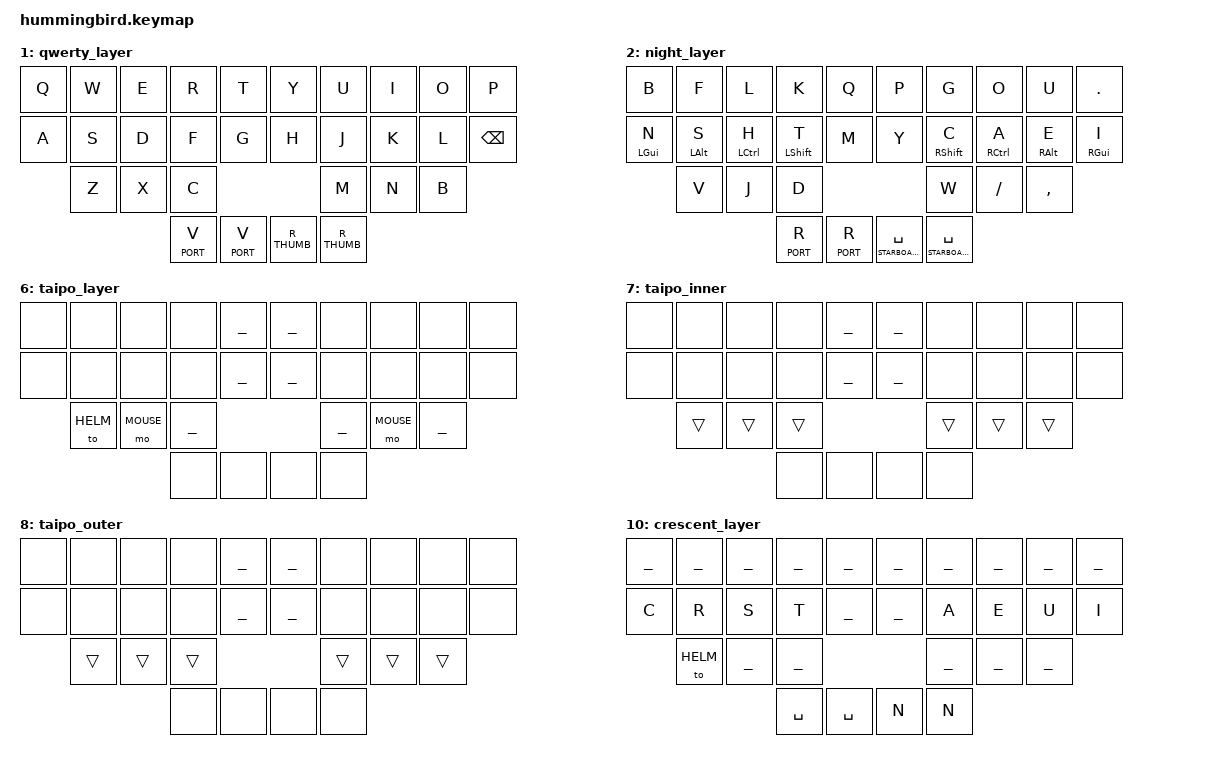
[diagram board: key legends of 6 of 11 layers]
#include "./key-labels/30.h"

#include "base.keymap"

ZMK_LAYER(helm_layer,
    // ╭─────────────┬─────────────┬─────────────┬─────────────┬─────────────╮   ╭─────────────┬─────────────┬─────────────┬─────────────┬─────────────╮
         LEFT_HELM_UPPER_ROW________________________________________________       RIGHT_HELM_UPPER_ROW_______________________________________________
    // ├─────────────┼─────────────┼─────────────┼─────────────┼─────────────┤   ├─────────────┼─────────────┼─────────────┼─────────────┼─────────────┤
         LEFT_HELM_MIDDLE_ROW_______________________________________________       RIGHT_HELM_MIDDLE_ROW______________________________________________
    // ╰─────────────┼─────────────┼─────────────┼─────────────┼─────────────╯   ╰─────────────┼─────────────┼─────────────┼─────────────┼─────────────╯
                       LEFT_HELM_LOWER_ROW____________________                                   RIGHT_HELM_LOWER_ROW___________________
    //               ╰─────────────┴─────────────┼─────────────┼─────────────╮   ╭─────────────┼─────────────┼─────────────┴─────────────╯
                                                   L_THUMB       L_THUMB           R_THUMB       R_THUMB
    //                                           ╰─────────────┴─────────────╯   ╰─────────────┴─────────────╯
)

// TODO make this qwerty
ZMK_LAYER(qwerty_layer,
    // ╭─────────────┬─────────────┬─────────────┬─────────────┬─────────────╮   ╭─────────────┬─────────────┬─────────────┬─────────────┬─────────────╮
         &kp Q         &kp W         &kp E         &kp R         &kp T             &kp Y         &kp U         &kp I         &kp O         &kp P
    // ├─────────────┼─────────────┼─────────────┼─────────────┼─────────────┤   ├─────────────┼─────────────┼─────────────┼─────────────┼─────────────┤
         &kp A         &kp S         &kp D         &kp F         &kp G             &kp H         &kp J         &kp K         &kp L         &kp BSPC
    // ╰─────────────┼─────────────┼─────────────┼─────────────┼─────────────╯   ╰─────────────┼─────────────┼─────────────┼─────────────┼─────────────╯
                       &kp Z         &kp X         &kp C                                         &kp M         &kp N         &kp B
    //               ╰─────────────┴─────────────┼─────────────┼─────────────╮   ╭─────────────┼─────────────┼─────────────┴─────────────╯
                                                   &ltp PORT V    &ltp PORT V        R_THUMB       R_THUMB
    //                                           ╰─────────────┴─────────────╯   ╰─────────────┴─────────────╯
)

// Night thumbs
#define PORT_R      &ltp PORT R
#define STARB_SPC   &lt STARBOARD SPC
// Night combos
ZMK_COMBO(night_z,     &kp Z,      LB2 LB1, NIGHT, COMBO_TERM_SLOW)
ZMK_COMBO(night_x,     &kp X,      LB3 LB2, NIGHT, COMBO_TERM_SLOW)
ZMK_COMBO(night_sqt,   &kp SQT,    RB1 RB2, NIGHT, COMBO_TERM_SLOW)
ZMK_COMBO(night_semi,  &kp SEMI,   RB2 RB3, NIGHT, COMBO_TERM_SLOW)
ZMK_LAYER(night_layer,
    // ╭─────────────┬─────────────┬─────────────┬─────────────┬─────────────╮   ╭─────────────┬─────────────┬─────────────┬─────────────┬─────────────╮
        &kp B         &kp F         &kp L         &kp K         &kp Q             &kp P         &kp G         &kp O         &kp U         &kp DOT
    // ├─────────────┼─────────────┼─────────────┼─────────────┼─────────────┤   ├─────────────┼─────────────┼─────────────┼─────────────┼─────────────┤
        &hml LGUI N   &hml LALT S   &hml LCTRL H  &hmls LSHFT T  &kp M             &kp Y         &hmrs RSHFT C  &hmr RCTRL A  &hmr RALT E   &hmr RGUI I
    // ╰─────────────┼─────────────┼─────────────┼─────────────┼─────────────╯   ╰─────────────┼─────────────┼─────────────┼─────────────┼─────────────╯
                      &kp V         &kp J         &kp D                                         &kp W         &kp SLASH     &kp COMMA
    //               ╰─────────────┴─────────────┼─────────────┼─────────────╮   ╭─────────────┼─────────────┼─────────────┴─────────────╯
                                                   PORT_R       PORT_R            STARB_SPC     STARB_SPC
    //                                           ╰─────────────┴─────────────╯   ╰─────────────┴─────────────╯
)

ZMK_LAYER(port_layer,
    // ╭─────────────┬─────────────┬─────────────┬─────────────┬─────────────╮   ╭─────────────┬─────────────┬─────────────┬─────────────┬─────────────╮
         LEFT_PORT_UPPER_ROW________________________________________________       RIGHT_PORT_UPPER_ROW_______________________________________________
    // ├─────────────┼─────────────┼─────────────┼─────────────┼─────────────┤   ├─────────────┼─────────────┼─────────────┼─────────────┼─────────────┤
         LEFT_PORT_MIDDLE_ROW_______________________________________________       RIGHT_PORT_MIDDLE_ROW______________________________________________
    // ╰─────────────┼─────────────┼─────────────┼─────────────┼─────────────╯   ╰─────────────┼─────────────┼─────────────┼─────────────┼─────────────╯
                       LEFT_PORT_LOWER_ROW____________________                                   RIGHT_PORT_LOWER_ROW___________________
    //               ╰─────────────┴─────────────┼─────────────┼─────────────╮   ╭─────────────┼─────────────┼─────────────┴─────────────╯
                                                   L_THUMB       L_THUMB           R_THUMB       R_THUMB
    //                                           ╰─────────────┴─────────────╯   ╰─────────────┴─────────────╯
)

ZMK_LAYER(starboard_layer,
    // ╭─────────────┬─────────────┬─────────────┬─────────────┬─────────────╮   ╭─────────────┬─────────────┬─────────────┬─────────────┬─────────────╮
         LEFT_STARBOARD_UPPER_ROW___________________________________________       RIGHT_STARBOARD_UPPER_ROW__________________________________________
    // ├─────────────┼─────────────┼─────────────┼─────────────┼─────────────┤   ├─────────────┼─────────────┼─────────────┼─────────────┼─────────────┤
         LEFT_STARBOARD_MIDDLE_ROW__________________________________________       RIGHT_STARBOARD_MIDDLE_ROW_________________________________________
    // ╰─────────────┼─────────────┼─────────────┼─────────────┼─────────────╯   ╰─────────────┼─────────────┼─────────────┼─────────────┼─────────────╯
                       LEFT_STARBOARD_LOWER_ROW_______________                                   RIGHT_STARBOARD_LOWER_ROW______________
    //               ╰─────────────┴─────────────┼─────────────┼─────────────╮   ╭─────────────┼─────────────┼─────────────┴─────────────╯
                                                   L_THUMB       L_THUMB           R_THUMB       R_THUMB
    //                                           ╰─────────────┴─────────────╯   ╰─────────────┴─────────────╯
)

ZMK_LAYER(aft_layer,
    // ╭─────────────┬─────────────┬─────────────┬─────────────┬─────────────╮   ╭─────────────┬─────────────┬─────────────┬─────────────┬─────────────╮
         LEFT_AFT_UPPER_ROW_________________________________________________       RIGHT_AFT_UPPER_ROW________________________________________________
    // ├─────────────┼─────────────┼─────────────┼─────────────┼─────────────┤   ├─────────────┼─────────────┼─────────────┼─────────────┼─────────────┤
         LEFT_AFT_MIDDLE_ROW________________________________________________       RIGHT_AFT_MIDDLE_ROW_______________________________________________
    // ╰─────────────┼─────────────┼─────────────┼─────────────┼─────────────╯   ╰─────────────┼─────────────┼─────────────┼─────────────┼─────────────╯
                       LEFT_AFT_LOWER_ROW_____________________                                   RIGHT_AFT_LOWER_ROW____________________
    //               ╰─────────────┴─────────────┼─────────────┼─────────────╮   ╭─────────────┼─────────────┼─────────────┴─────────────╯
                                                   L_THUMB       L_THUMB           R_THUMB       R_THUMB
    //                                           ╰─────────────┴─────────────╯   ╰─────────────┴─────────────╯
)

ZMK_LAYER(taipo_layer,
    // ╭─────────────┬─────────────┬─────────────┬─────────────┬─────────────╮   ╭─────────────┬─────────────┬─────────────┬─────────────┬─────────────╮
         &none         &none         &none         &none         ___               ___           &none         &none         &none         &none
    // ├─────────────┼─────────────┼─────────────┼─────────────┼─────────────┤   ├─────────────┼─────────────┼─────────────┼─────────────┼─────────────┤
         &none         &none         &none         &none         ___               ___           &none         &none         &none         &none
    // ╰─────────────┼─────────────┼─────────────┼─────────────┼─────────────╯   ╰─────────────┼─────────────┼─────────────┼─────────────┼─────────────╯
                       &to HELM      &mo MOUSE     ___                                           ___           &mo MOUSE     ___
    //               ╰─────────────┴─────────────┼─────────────┼─────────────╮   ╭─────────────┼─────────────┼─────────────┴─────────────╯
                                                   &none         &none             &none         &none
    //                                           ╰─────────────┴─────────────╯   ╰─────────────┴─────────────╯
)
// Add momentary mouse to both thumbs
ZMK_COMBO(Lmouse, &mo MOUSE, ITL OTL, TAIPO, COMBO_TERM_FAST)
ZMK_COMBO(Rmouse, &mo MOUSE, ITR OTR, TAIPO, COMBO_TERM_FAST)
ZMK_COMBO(Bmouse, &mo MOUSE, ITL ITR, TAIPO, COMBO_TERM_FAST)

ZMK_LAYER(taipo_inner,
    // ╭─────────────┬─────────────┬─────────────┬─────────────┬─────────────╮   ╭─────────────┬─────────────┬─────────────┬─────────────┬─────────────╮
         &none         &none         &none         &none         ___               ___           &none         &none         &none         &none
    // ├─────────────┼─────────────┼─────────────┼─────────────┼─────────────┤   ├─────────────┼─────────────┼─────────────┼─────────────┼─────────────┤
         &none         &none         &none         &none         ___               ___           &none         &none         &none         &none
    // ╰─────────────┼─────────────┼─────────────┼─────────────┼─────────────╯   ╰─────────────┼─────────────┼─────────────┼─────────────┼─────────────╯
                       &trans        &trans        &trans                                        &trans        &trans        &trans
    //               ╰─────────────┴─────────────┼─────────────┼─────────────╮   ╭─────────────┼─────────────┼─────────────┴─────────────╯
                                                   &none         &none             &none         &none
    //                                           ╰─────────────┴─────────────╯   ╰─────────────┴─────────────╯
)

ZMK_LAYER(taipo_outer,
    // ╭─────────────┬─────────────┬─────────────┬─────────────┬─────────────╮   ╭─────────────┬─────────────┬─────────────┬─────────────┬─────────────╮
         &none         &none         &none         &none         ___               ___           &none         &none         &none         &none
    // ├─────────────┼─────────────┼─────────────┼─────────────┼─────────────┤   ├─────────────┼─────────────┼─────────────┼─────────────┼─────────────┤
         &none         &none         &none         &none         ___               ___           &none         &none         &none         &none
    // ╰─────────────┼─────────────┼─────────────┼─────────────┼─────────────╯   ╰─────────────┼─────────────┼─────────────┼─────────────┼─────────────╯
                       &trans        &trans        &trans                                        &trans        &trans        &trans
    //               ╰─────────────┴─────────────┼─────────────┼─────────────╮   ╭─────────────┼─────────────┼─────────────┴─────────────╯
                                                   &none         &none             &none         &none
    //                                           ╰─────────────┴─────────────╯   ╰─────────────┴─────────────╯
)

ZMK_LAYER(mouse_layer,
    // ╭─────────────┬─────────────┬─────────────┬─────────────┬─────────────╮   ╭─────────────┬─────────────┬─────────────┬─────────────┬─────────────╮
         MOUSE_SCROLL_________________________________________   ___               ___           MOUSE_SCROLL_________________________________________
    // ├─────────────┼─────────────┼─────────────┼─────────────┼─────────────┤   ├─────────────┼─────────────┼─────────────┼─────────────┼─────────────┤
         MOUSE_MOVE___________________________________________   ___               ___           MOUSE_MOVE___________________________________________
    // ╰─────────────┼─────────────┼─────────────┼─────────────┼─────────────╯   ╰─────────────┼─────────────┼─────────────┼─────────────┼─────────────╯
                       MOUSE_BUTTONS__________________________                                   MOUSE_BUTTONS__________________________
    //               ╰─────────────┴─────────────┼─────────────┼─────────────╮   ╭─────────────┼─────────────┼─────────────┴─────────────╯
                                                   &to TAIPO     &to TAIPO         &to HELM      &to HELM
    //                                           ╰─────────────┴─────────────╯   ╰─────────────┴─────────────╯
)

ZMK_LAYER(crescent_layer,
    // ╭─────────────┬─────────────┬─────────────┬─────────────┬─────────────╮   ╭─────────────┬─────────────┬─────────────┬─────────────┬─────────────╮
         ___           ___           ___           ___           ___               ___           ___           ___           ___           ___
    // ├─────────────┼─────────────┼─────────────┼─────────────┼─────────────┤   ├─────────────┼─────────────┼─────────────┼─────────────┼─────────────┤
         &kp C         &kp R         &kp S         &kp T         ___               ___           &kp A         &kp E         &kp U         &kp I
    // ╰─────────────┼─────────────┼─────────────┼─────────────┼─────────────╯   ╰─────────────┼─────────────┼─────────────┼─────────────┼─────────────╯
                       &to HELM      ___           ___                                           ___           ___           ___
    //               ╰─────────────┴─────────────┼─────────────┼─────────────╮   ╭─────────────┼─────────────┼─────────────┴─────────────╯
                                                   &kp SPC       &kp SPC           &kp N         &kp N
    //                                           ╰─────────────┴─────────────╯   ╰─────────────┴─────────────╯
)

/* vim: set tw=180 ft=c: */
